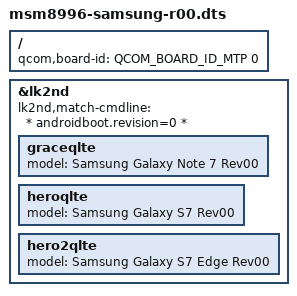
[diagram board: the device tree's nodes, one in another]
// SPDX-License-Identifier: BSD-3-Clause

#include "msm8996-samsung.dtsi"

/ {
	qcom,board-id = <QCOM_BOARD_ID_MTP 0>;
};

&lk2nd {
	lk2nd,match-cmdline = "* androidboot.revision=0 *";

	graceqlte {
		model = "Samsung Galaxy Note 7 Rev00";
	};

	heroqlte {
		model = "Samsung Galaxy S7 Rev00";
	};

	hero2qlte {
		model = "Samsung Galaxy S7 Edge Rev00";
	};
};
